VERSION ""

NS_ :

BS_:

BU_:

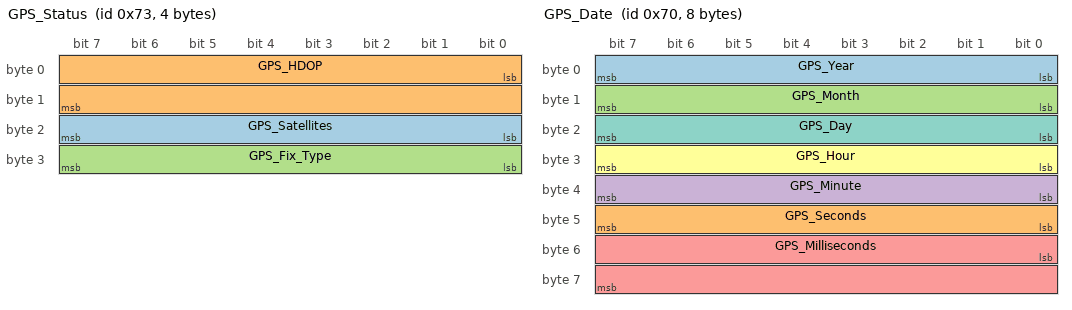
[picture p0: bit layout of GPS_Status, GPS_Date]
BO_ 115 GPS_Status: 4 Vector__XXX
 SG_ GPS_Satellites : 16|8@1+ (1,0) [0|255] "" Vector__XXX
 SG_ GPS_HDOP : 0|16@1- (0.01,0) [-327.68|327.67] "" Vector__XXX
 SG_ GPS_Fix_Type : 24|8@1+ (1,0) [0|255] "" Vector__XXX

BO_ 114 GPS_Speed: 4 Vector__XXX
 SG_ GPS_Speed_MS : 0|16@1- (0.01,0) [-327.68|327.67] "m/s" Vector__XXX
 SG_ GPS_Course_DEG : 16|16@1- (0.01,0) [-327.68|327.67] "deg" Vector__XXX

BO_ 113 GPS_Position: 8 Vector__XXX
 SG_ GPS_Longitude_DEG : 32|32@1- (1E-007,0) [-214.7483648|214.7483647] "" Vector__XXX
 SG_ GPS_Latitude_DEG : 0|32@1- (1E-007,0) [-214.7483648|214.7483647] "" Vector__XXX

BO_ 112 GPS_Date: 8 Vector__XXX
 SG_ GPS_Year : 0|8@1+ (1,2000) [2000|2255] "" Vector__XXX
 SG_ GPS_Seconds : 40|8@1+ (1,0) [0|255] "" Vector__XXX
 SG_ GPS_Month : 8|8@1+ (1,0) [0|255] "" Vector__XXX
 SG_ GPS_Minute : 32|8@1+ (1,0) [0|255] "" Vector__XXX
 SG_ GPS_Milliseconds : 48|16@1+ (1,0) [0|65535] "" Vector__XXX
 SG_ GPS_Hour : 24|8@1+ (1,0) [0|255] "" Vector__XXX
 SG_ GPS_Day : 16|8@1+ (1,0) [0|255] "" Vector__XXX
